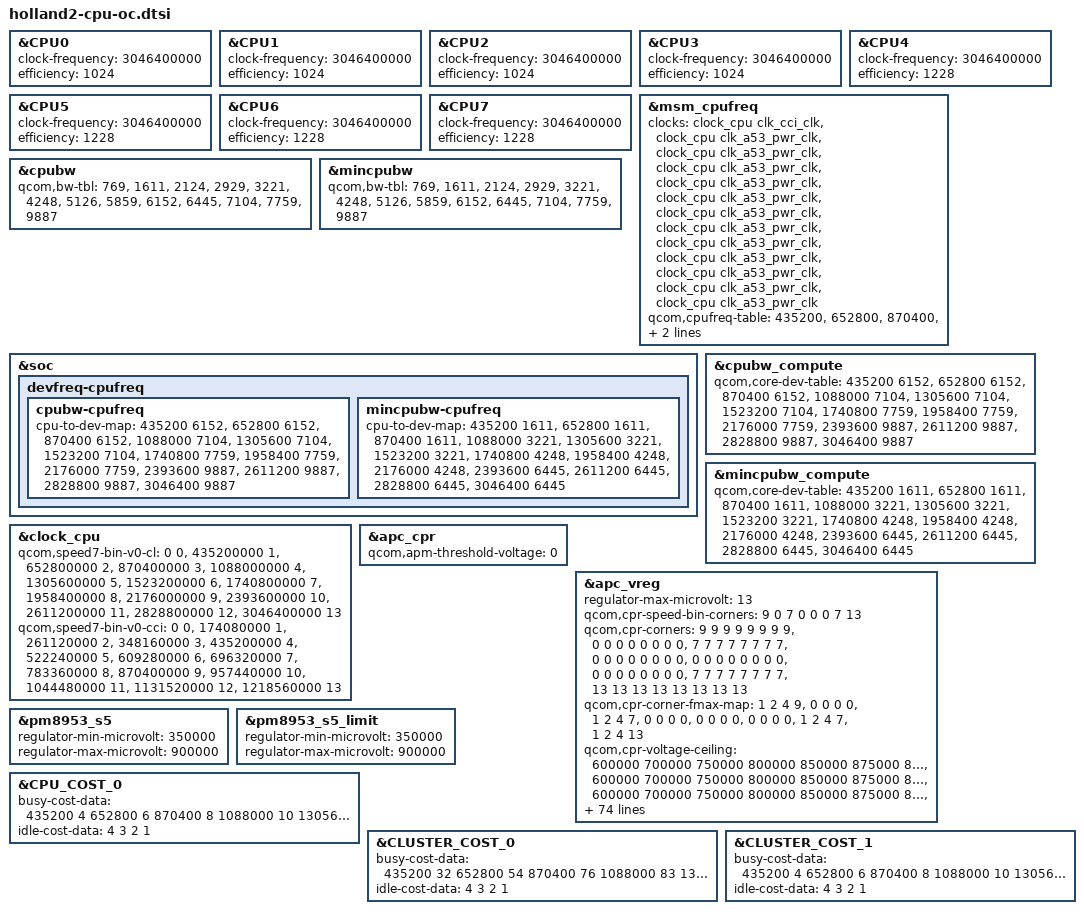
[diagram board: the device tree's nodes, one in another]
/* Copyright (c) 2020, The Linux Foundation. All rights reserved.
*  Copyright (c) 2020, Jebaitedneko.
*
* This program is free software; you can redistribute it and/or modify
* it under the terms of the GNU General Public License version 2 and
* only version 2 as published by the Free Software Foundation.
*
* This program is distributed in the hope that it will be useful,
* but WITHOUT ANY WARRANTY; without even the implied warranty of
* MERCHANTABILITY or FITNESS FOR A PARTICULAR PURPOSE.  See the
* GNU General Public License for more details.
*/

&CPU0 {
	clock-frequency = <3046400000>;
	efficiency = <1024>; // 1024
};
&CPU1 {
	clock-frequency = <3046400000>;
	efficiency = <1024>; // 1024
};
&CPU2 {
	clock-frequency = <3046400000>;
	efficiency = <1024>; // 1024
};
&CPU3{
	clock-frequency = <3046400000>;
	efficiency = <1024>; // 1024
};
&CPU4 {
	clock-frequency = <3046400000>;
	efficiency = <1228>; // 1126
};
&CPU5 {
	clock-frequency = <3046400000>;
	efficiency = <1228>; // 1126
};
&CPU6 {
	clock-frequency = <3046400000>;
	efficiency = <1228>; // 1126
};
&CPU7{
	clock-frequency = <3046400000>;
	efficiency = <1228>; // 1126
};

&msm_cpufreq {

	clock-names = "l2_clk", "cpu0_clk", "cpu1_clk",
				"cpu2_clk", "cpu3_clk", "cpu4_clk",
				"cpu5_clk", "cpu6_clk", "cpu7_clk",
				"cpu8_clk", "cpu9_clk", "cpu10_clk",
				"cpu11_clk";

	clocks = <&clock_cpu clk_cci_clk>,
			<&clock_cpu clk_a53_pwr_clk>,
			<&clock_cpu clk_a53_pwr_clk>,
			<&clock_cpu clk_a53_pwr_clk>,
			<&clock_cpu clk_a53_pwr_clk>,
			<&clock_cpu clk_a53_pwr_clk>,
			<&clock_cpu clk_a53_pwr_clk>,
			<&clock_cpu clk_a53_pwr_clk>,
			<&clock_cpu clk_a53_pwr_clk>,
			<&clock_cpu clk_a53_pwr_clk>,
			<&clock_cpu clk_a53_pwr_clk>,
			<&clock_cpu clk_a53_pwr_clk>,
			<&clock_cpu clk_a53_pwr_clk>;

	qcom,cpufreq-table =
		<  435200 >,
		<  652800 >,
		<  870400 >,
		< 1088000 >,
		< 1305600 >,
		< 1523200 >,
		< 1740800 >,
		< 1958400 >,
		< 2176000 >,
		< 2393600 >,
		< 2611200 >,
		< 2828800 >,
		< 3046400 >;
};

&cpubw {

	qcom,bw-tbl =
		<   769 /*  100.8 MHz  */ >,
		<  1611 /*  211.2 MHz  */ >,
		<  2124 /*  278.4 MHz  */ >,
		<  2929 /*  384   MHz  */ >,
		<  3221 /*  422.4 MHz  */ >,
		<  4248 /*  556.8 MHz  */ >,
		<  5126 /*  672   MHz  */ >,
		<  5859 /*  768   MHz  */ >,
		<  6152 /*  806.4 MHz  */ >,
		<  6445 /*  844.8 MHz  */ >,
		<  7104 /*  931.2 MHz  */ >,
		<  7759 /*  1017.0 MHz */ >,
		<  9887 /*  1296.0 MHz */ >;
};

&mincpubw {

	qcom,bw-tbl =
		<   769 /*  100.8 MHz  */ >,
		<  1611 /*  211.2 MHz  */ >,
		<  2124 /*  278.4 MHz  */ >,
		<  2929 /*  384   MHz  */ >,
		<  3221 /*  422.4 MHz  */ >,
		<  4248 /*  556.8 MHz  */ >,
		<  5126 /*  672   MHz  */ >,
		<  5859 /*  768   MHz  */ >,
		<  6152 /*  806.4 MHz  */ >,
		<  6445 /*  844.8 MHz  */ >,
		<  7104 /*  931.2 MHz  */ >,
		<  7759 /*  1017.0 MHz */ >,
		<  9887 /*  1296.0 MHz */ >;
};

&soc {

	devfreq-cpufreq {

		cpubw-cpufreq {

			cpu-to-dev-map =
				<  435200 6152>,
				<  652800 6152>,
				<  870400 6152>,
				< 1088000 7104>,
				< 1305600 7104>,
				< 1523200 7104>,
				< 1740800 7759>,
				< 1958400 7759>,
				< 2176000 7759>,
				< 2393600 9887>,
				< 2611200 9887>,
				< 2828800 9887>,
				< 3046400 9887>;
		};

		mincpubw-cpufreq {

			cpu-to-dev-map =
				<  435200 1611>,
				<  652800 1611>,
				<  870400 1611>,
				< 1088000 3221>,
				< 1305600 3221>,
				< 1523200 3221>,
				< 1740800 4248>,
				< 1958400 4248>,
				< 2176000 4248>,
				< 2393600 6445>,
				< 2611200 6445>,
				< 2828800 6445>,
				< 3046400 6445>;
		};
	};
};

&cpubw_compute {

	qcom,core-dev-table =
		<  435200 6152>,
		<  652800 6152>,
		<  870400 6152>,
		< 1088000 7104>,
		< 1305600 7104>,
		< 1523200 7104>,
		< 1740800 7759>,
		< 1958400 7759>,
		< 2176000 7759>,
		< 2393600 9887>,
		< 2611200 9887>,
		< 2828800 9887>,
		< 3046400 9887>;
};

&mincpubw_compute {

	qcom,core-dev-table =
		<  435200 1611>,
		<  652800 1611>,
		<  870400 1611>,
		< 1088000 3221>,
		< 1305600 3221>,
		< 1523200 3221>,
		< 1740800 4248>,
		< 1958400 4248>,
		< 2176000 4248>,
		< 2393600 6445>,
		< 2611200 6445>,
		< 2828800 6445>,
		< 3046400 6445>;
};

&clock_cpu {
	qcom,speed7-bin-v0-cl =
		<          0 0>,
		<  435200000 1>,  // 4352 x 1.0
		<  652800000 2>,  // 4352 x 1.5
		<  870400000 3>,  // 4352 x 2.0
		< 1088000000 4>,  // 4352 x 2.5
		< 1305600000 5>,  // 4352 x 3.0
		< 1523200000 6>,  // 4352 x 3.5
		< 1740800000 7>,  // 4352 x 4.0
		< 1958400000 8>,  // 4352 x 4.5
		< 2176000000 9>,  // 4352 x 5.0
		< 2393600000 10>, // 4352 x 5.5
		< 2611200000 11>, // 4352 x 6.0
		< 2828800000 12>, // 4352 x 6.5
		< 3046400000 13>; // 4352 x 7.0
	qcom,speed7-bin-v0-cci =
		<          0 0>,
		<  174080000 1>,   //  435200000 / 2.5
		<  261120000 2>,   //  652800000 / 2.5
		<  348160000 3>,   //  870400000 / 2.5
		<  435200000 4>,   // 1088000000 / 2.5
		<  522240000 5>,   // 1305600000 / 2.5
		<  609280000 6>,   // 1523200000 / 2.5
		<  696320000 7>,   // 1740800000 / 2.5
		<  783360000 8>,   // 1958400000 / 2.5
		<  870400000 9>,   // 2176000000 / 2.5
		<  957440000 10>,  // 2393600000 / 2.5
		< 1044480000 11>,  // 2611200000 / 2.5
		< 1131520000 12>,  // 2828800000 / 2.5
		< 1218560000 13>;  // 3046400000 / 2.5
};

&apc_cpr {

	/delete-property/ qcom,cpr-aging-ref-voltage;
	/delete-property/ qcom,cpr-aging-allowed-reg-mask;
	/delete-property/ qcom,cpr-aging-allowed-reg-value;
	/delete-property/ qcom,apm-hysteresis-voltage;
	qcom,apm-threshold-voltage = <0>;
};

&apc_vreg {

	/delete-property/ qcom,cpr-open-loop-voltage-fuse-adjustment;
	/delete-property/ qcom,cpr-open-loop-voltage-adjustment;
	/delete-property/ qcom,cpr-open-loop-voltage-min-diff;
	/delete-property/ qcom,cpr-scaled-open-loop-voltage-as-ceiling;
	/delete-property/ qcom,cpr-aging-derate;
	/delete-property/ qcom,cpr-aging-max-voltage-adjustment;
	/delete-property/ qcom,cpr-aging-ref-corner;
	/delete-property/ qcom,cpr-aging-ro-scaling-factor;
	/delete-property/ qcom,allow-aging-voltage-adjustment;
	/delete-property/ qcom,allow-voltage-interpolation;
	/delete-property/ qcom,allow-quotient-interpolation;

	regulator-max-microvolt = <13>;

	qcom,cpr-speed-bin-corners =
		<9 0 7 0 0 0 7 13>;

	qcom,cpr-corners =
		/* Speed bin 0 */
		<9 9 9 9 9 9 9 9>,

		/* Speed bin 1 */
		<0 0 0 0 0 0 0 0>,

		/* Speed bin 2 */
		<7 7 7 7 7 7 7 7>,

		/* Speed bin 3..5 */
		<0 0 0 0 0 0 0 0>,
		<0 0 0 0 0 0 0 0>,
		<0 0 0 0 0 0 0 0>,

		/* Speed bin 6 */
		<7 7 7 7 7 7 7 7>,

		/* Speed bin 7 */
		<13 13 13 13 13 13 13 13>;

	qcom,cpr-corner-fmax-map =
		/* Speed bin 0 */
		<1 2 4 9>,

		/* Speed bin 1 */
		<0 0 0 0>,

		/* Speed bin 2 */
		<1 2 4 7>,

		/* Speed bin 3..5 */
		<0 0 0 0>,
		<0 0 0 0>,
		<0 0 0 0>,

		/* Speed bin 6 */
		<1 2 4 7>,

		/* Speed bin 7 */
		<1 2 4 13>;

	qcom,cpr-voltage-ceiling =
		/* Speed bin 0 */
		<600000  700000 750000 800000 850000
			875000 875000 900000 900000>,

		/* Speed bin 2 */
		<600000  700000 750000 800000 850000
			875000 875000>,

		/* Speed bin 6 */
		<600000  700000 750000 800000 850000
			875000 875000>,

		/* Speed bin 7 */
		<600000  700000 750000 800000 850000
			850000 875000 875000 900000 900000 900000 900000 900000>;

	qcom,cpr-voltage-floor =
		/* Speed bin 0 */
		<350000  350000 350000 350000 350000
			350000  350000 350000 350000>,

		/* Speed bin 2 */
		<350000  350000 350000 350000 350000
			350000  350000>,

		/* Speed bin 6 */
		<350000  350000 350000 350000 350000
			350000  350000>,

		/* Speed bin 7 */
		<350000  350000 350000 350000 350000
			350000  350000 350000 350000 350000 350000 350000 350000>;

	qcom,cpr-floor-to-ceiling-max-range =
	/* Speed bin 0; CPR rev 0..7 */
		<    0     0     0     0     0
			0     0     0     0>,
		<300000 300000 300000 300000 300000
		300000 300000 300000 300000>,
		<300000 300000 300000 300000 300000
		300000 300000 300000 300000>,
		<300000 300000 300000 300000 300000
		300000 300000 300000 300000>,
		<300000 300000 300000 300000 300000
		300000 300000 300000 300000>,
		<300000 300000 300000 300000 300000
		300000 300000 300000 300000>,
		<300000 300000 300000 300000 300000
		300000 300000 300000 300000>,
		<300000 300000 300000 300000 300000
		300000 300000 300000 300000>,

	/* Speed bin 2; CPR rev 0..7 */
		<    0     0     0     0     0
			0     0>,
		<300000 300000 300000 300000 300000
		300000 300000>,
		<300000 300000 300000 300000 300000
		300000 300000>,
		<300000 300000 300000 300000 300000
		300000 300000>,
		<300000 300000 300000 300000 300000
		300000 300000>,
		<300000 300000 300000 300000 300000
		300000 300000>,
		<300000 300000 300000 300000 300000
		300000 300000>,
		<300000 300000 300000 300000 300000
		300000 300000>,

	/* Speed bin 6; CPR rev 0..7 */
		<    0     0     0     0     0
			0     0>,
		<300000 300000 300000 300000 300000
		300000 300000>,
		<300000 300000 300000 300000 300000
		300000 300000>,
		<300000 300000 300000 300000 300000
		300000 300000>,
		<300000 300000 300000 300000 300000
		300000 300000>,
		<300000 300000 300000 300000 300000
		300000 300000>,
		<300000 300000 300000 300000 300000
		300000 300000>,
		<300000 300000 300000 300000 300000
		300000 300000>,

	/* Speed bin 7; CPR rev 0..7 */
		<(-1) (-1) (-1) (-1) (-1)
		(-1) (-1) (-1) (-1) (-1) (-1) (-1) (-1)>,
		<(-1) (-1) (-1) (-1) (-1)
		(-1) (-1) (-1) (-1) (-1) (-1) (-1) (-1)>,
		<(-1) (-1) (-1) (-1) (-1)
		(-1) (-1) (-1) (-1) (-1) (-1) (-1) (-1)>,
		<(-1) (-1) (-1) (-1) (-1)
		(-1) (-1) (-1) (-1) (-1) (-1) (-1) (-1)>,
		<(-1) (-1) (-1) (-1) (-1)
		(-1) (-1) (-1) (-1) (-1) (-1) (-1) (-1)>,
		<(-1) (-1) (-1) (-1) (-1)
		(-1) (-1) (-1) (-1) (-1) (-1) (-1) (-1)>,
		<(-1) (-1) (-1) (-1) (-1)
		(-1) (-1) (-1) (-1) (-1) (-1) (-1) (-1)>,
		<(-1) (-1) (-1) (-1) (-1)
		(-1) (-1) (-1) (-1) (-1) (-1) (-1) (-1)>;

	qcom,cpr-misc-fuse-voltage-adjustment =
		/* Speed bin 0; misc fuse 0..1 */
		<    0     0     0     0      0
				0     0     0     0>,
		<    0     0 30000     0      0
				0     0     0     0>,

		/* Speed bin 2; misc fuse 0..1 */
		<    0     0     0     0      0
				0     0>,
		<    0     0 30000     0      0
				0     0>,

		/* Speed bin 6; misc fuse 0..1 */
		<    0     0     0     0      0
				0     0>,
		<    0     0 30000     0      0
				0     0>,

		/* Speed bin 7; misc fuse 0..1 */
		<    0     0     0     0      0
				0     0     0     0     0     0     0     0>,
		<    0     0     0    0      0
				0     0     0     0     0     0     0     0>;

	qcom,mem-acc-voltage =
		/* Speed bin 0 */
		<1 1 2 2 2 2 2 2 2>,

		/* Speed bin 2 */
		<1 1 2 2 2 2 2>,

		/* Speed bin 6 */
		<1 1 2 2 2 2 2>,

		/* Speed bin 7 */
		<1 1 2 2 2 2 2 2 2 2 2 2 2>;

	qcom,corner-frequencies =
		/* Speed bin 0 */
		<435200000 1036800000 1401600000
		1689600000 1804800000 1958400000
		2016000000 2208000000 2400000000>,

		/* Speed bin 2 */
		<435200000 1036800000 1401600000
		1689600000 1804800000 1958400000
		2016000000>,

		/* Speed bin 6 */
		<435200000 1036800000 1401600000
		1689600000 1804800000 1958400000
		2016000000>,

		/* Speed bin 7 */
		<
		435200000
		652800000
		870400000
		1088000000
		1305600000
		1523200000
		1740800000
		1958400000
		2176000000
		2393600000
		2611200000
		2828800000
		3046400000
		>;

	qcom,cpr-closed-loop-voltage-fuse-adjustment =
		/* Speed bin 0; CPR rev 0..7 */
		<      0        0        0      0>,
		<  10000 (-15000)        0  25000>,
		<  10000 (-15000)        0  25000>,
		<(-5000) (-30000) (-15000)  10000>,
		<      0        0        0      0>,
		<      0        0        0      0>,
		<      0        0        0      0>,
		<      0        0        0      0>,

		/* Speed bin 1; CPR rev 0..7 */
		<      0        0        0      0>,
		<      0        0        0      0>,
		<      0        0        0      0>,
		<      0        0        0      0>,
		<      0        0        0      0>,
		<      0        0        0      0>,
		<      0        0        0      0>,
		<      0        0        0      0>,

		/* Speed bin 2; CPR rev 0..7 */
		<      0        0        0      0>,
		<  10000 (-15000)        0  25000>,
		<  10000 (-15000)        0  25000>,
		<(-5000) (-30000) (-15000)  10000>,
		<      0        0        0      0>,
		<      0        0        0      0>,
		<      0        0        0      0>,
		<      0        0        0      0>,

		/* Speed bin 3; CPR rev 0..7 */
		<      0        0        0      0>,
		<      0        0        0      0>,
		<      0        0        0      0>,
		<      0        0        0      0>,
		<      0        0        0      0>,
		<      0        0        0      0>,
		<      0        0        0      0>,
		<      0        0        0      0>,

		/* Speed bin 4; CPR rev 0..7 */
		<      0        0        0      0>,
		<      0        0        0      0>,
		<      0        0        0      0>,
		<      0        0        0      0>,
		<      0        0        0      0>,
		<      0        0        0      0>,
		<      0        0        0      0>,
		<      0        0        0      0>,

		/* Speed bin 5; CPR rev 0..7 */
		<      0        0        0      0>,
		<      0        0        0      0>,
		<      0        0        0      0>,
		<      0        0        0      0>,
		<      0        0        0      0>,
		<      0        0        0      0>,
		<      0        0        0      0>,
		<      0        0        0      0>,

		/* Speed bin 6; CPR rev 0..7 */
		<      0        0        0      0>,
		<  10000 (-15000)        0  25000>,
		<  10000 (-15000)        0  25000>,
		<(-5000) (-30000) (-15000)  10000>,
		<      0        0        0      0>,
		<      0        0        0      0>,
		<      0        0        0      0>,
		<      0        0        0      0>,

		/* Speed bin 7; CPR rev 0..7 */
		<      0        0        0      0>,
		<      0        0        0      0>,
		<      0        0        0      0>,
		<      0        0        0      0>,
		<      0        0        0      0>,
		<      0        0        0      0>,
		<      0        0        0      0>,
		<      0        0        0      0>;
};

&pm8953_s5 {
	regulator-min-microvolt = <350000>; /* Default 400000 */
	regulator-max-microvolt = <900000>; /* Default 1140000 */
};

&pm8953_s5_limit {
	regulator-min-microvolt = <350000>; /* Default 400000 */
	regulator-max-microvolt = <900000>; /* Default 1140000 */
};

&CPU_COST_0 {
	busy-cost-data = <
		435200    4
		652800    6
		870400    8
		1088000   10
		1305600   15
		1523200   20
		1740800   24
		1958400   36
		2176000   48
		2393600   55
		2611200   65
		2828800   75
		3046400   85
	>;
	idle-cost-data = <
		4 3 2 1
	>;
};

&CLUSTER_COST_0 {
	busy-cost-data = <
		435200    32
		652800    54
		870400    76
		1088000   83
		1305600   95
		1523200  107
		1740800  114
		1958400  126
		2176000  138
		2393600  152
		2611200  174
		2828800  196
		3046400  210
	>;
	idle-cost-data = <
		4 3 2 1
	>;
};

&CLUSTER_COST_1 {
	busy-cost-data = <
		435200    4
		652800    6
		870400    8
		1088000   10
		1305600   15
		1523200   20
		1740800   92
		1958400  102
		2176000  112
		2393600  151
		2611200  173
		2828800  195
		3046400  210
	>;
	idle-cost-data = <
		4 3 2 1
	>;
};
